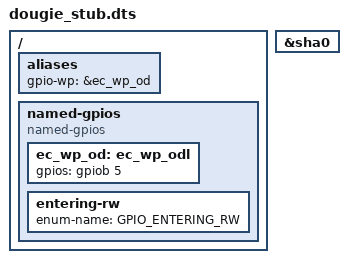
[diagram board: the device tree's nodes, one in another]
/* Copyright 2026 The ChromiumOS Authors
 * Use of this source code is governed by a BSD-style license that can be
 * found in the LICENSE file.
 */

/* Project-specific overrides */
&sha0 {
	status = "okay";
};

/ {
	aliases {
		gpio-wp = &ec_wp_od;
	};

	named-gpios {
		compatible = "named-gpios";

		ec_wp_od: ec_wp_odl {
			/* Physical High = Software True (Protected) */
			gpios = <&gpiob 5 GPIO_ACTIVE_HIGH>;
		};
		/* unimplemented GPIOs */
		entering-rw {
			enum-name = "GPIO_ENTERING_RW";
		};
	};
};
